# gcr_me18 register map
Registers are access not given, no defined reset value unless marked. A register's access mark holds for its fields unless they carry their own. Offsets are from the block's base; lines under a group give offsets from that group; [hi:lo] are bit positions; {n}, {i} and the like mark numbered series; 'fields as' and 'values as' point back to an identical list; <NAME> marks a mode.

## Memory map
0x40000000 GCR size 0x400 — Global Control Registers.

## GCR — Global Control Registers.
Base 0x40000000
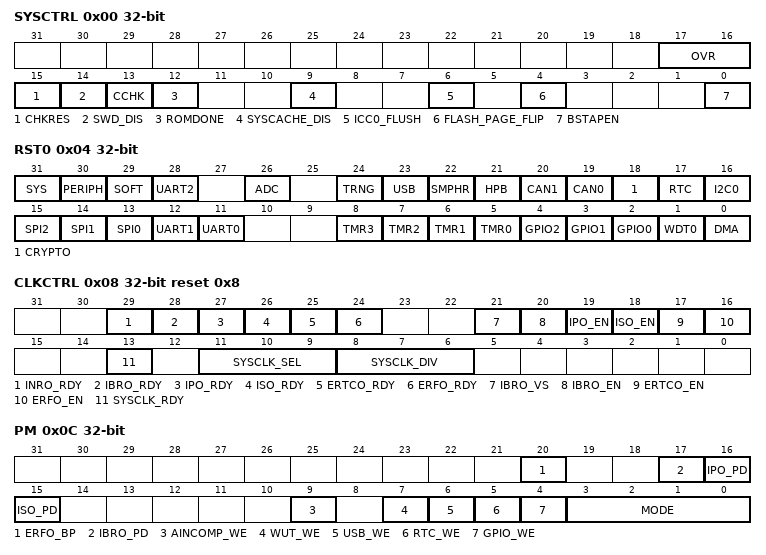
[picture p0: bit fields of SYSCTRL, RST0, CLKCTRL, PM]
0x00 SYSCTRL — System Control.
  [17:16] OVR — Operating Voltage Range.
    0=V0_9 (0.9V); 1=V1_0 (1.0V); 2=V1_1 (1.1V)
  [15] CHKRES — ROM Checksum Result. This bit is only valid when CHKRD=1.
    0=pass (ROM Checksum Correct.); 1=fail (ROM Checksum Fail.)
  [14] SWD_DIS — Serial Wire Debug Disable. This bit is used to disable the serial wire debug interface This bit is only writeable if (FMV lock word is not programmed) or if (ICE lock word is not programmed and the ROM_DONE bit is not set).
  [13] CCHK — Compute ROM Checksum. This bit is self-cleared when calculation is completed. Once set, software clearing this bit is ignored and the bit will remain set until the operation is completed.
    0=complete (No operation/complete.); 1=Start operation
  [12] ROMDONE — ROM_DONE status. Used to disable SWD interface during system initialization procedure
  [9] SYSCACHE_DIS — System Cache Disable.
  [6] ICC0_FLUSH — Code Cache Flush. This bit is used to flush the code caches and the instruction buffer of the Cortex-M4.
    0=Normal Code Cache Operation; 1=flush (Code Caches and CPU instruction buffer are flushed)
  [4] FLASH_PAGE_FLIP — Flips the Flash bottom and top halves. (Depending on the total flash size, each half is either 256K or 512K). Initiating a flash page flip will cause a flush of both the data buffer on the DCODE bus and the internal instruction buffer.
    0=normal (Physical layout matches logical layout.); 1=swapped (Bottom half mapped to logical top half and vice versa.)
  [0] BSTAPEN — Boundary Scan TAP enable. When enabled, the JTAG port is conneted to the Boundary Scan TAP instead of the ARM ICE.
0x04 RST0 — Reset.
  [all] fields
    0=reset_done (Reset complete.); 1=busy (Starts Reset or indicates reset in progress.)
  [31] SYS — System Reset. Setting this bit to 1 resets the CPU core and all peripherals, including the watchdog timer.
  [30] PERIPH — Peripheral Reset. Setting this bit to 1 resets all peripherals. The CPU core, the watchdog timer, and all GPIO pins are unaffected by this reset.
  [29] SOFT — Soft Reset. Setting this bit to 1 resets everything except the CPU and the watchdog timer.
  [28] UART2 — UART2 Reset. Setting this bit to 1 resets all UART 2 blocks.
  [26] ADC — ADC Reset.
  [24] TRNG — TRNG Reset. This reset is only available during the manufacture testing phase.
  [23] USB — USB Reset.
  [22] SMPHR — Semaphore Reset.
  [21] HPB — Hyperbus Reset.
  [20] CAN1 — CAN1 Reset.
  [19] CAN0 — CAN0 Reset.
  [18] CRYPTO — Crypto Reset.
  [17] RTC — Real Time Clock Reset.
  [16] I2C0 — I2C 0 Reset.
  [15] SPI2 — SPI 2 Reset. Setting this bit to 1 resets all SPI 2 blocks.
  [14] SPI1 — SPI 1 Reset. Setting this bit to 1 resets all SPI 1 blocks.
  [13] SPI0 — SPI 0 Reset. Setting this bit to 1 resets all SPI 0 blocks.
  [12] UART1 — UART 1 Reset. Setting this bit to 1 resets all UART 1 blocks.
  [11] UART0 — UART 0 Reset. Setting this bit to 1 resets all UART 0 blocks.
  [n+5] TMR{n} (n=0..3) — Timer {n} Reset. Setting this bit to 1 resets Timer {n} blocks.
  [4] GPIO2 — GPIO2 Reset. Setting this bit to 1 resets GPIO2 pins to their default states.
  [3] GPIO1 — GPIO1 Reset. Setting this bit to 1 resets GPIO1 pins to their default states.
  [2] GPIO0 — GPIO0 Reset. Setting this bit to 1 resets GPIO0 pins to their default states.
  [1] WDT0 — Watchdog Timer 0 Reset.
  [0] DMA — DMA Reset.
0x08 CLKCTRL reset 0x8 — Clock Control.
  [29] INRO_RDY ro — 8 kHz Low Frequency Reference Clock Ready.
    0=not (Is not Ready.); 1=ready (Is Ready.)
  [28] IBRO_RDY ro — 7.3725 MHz HIRC Ready.
    0=not (Is not Ready.); 1=ready (Is Ready.)
  [27] IPO_RDY ro — 100 MHz Clock Ready.
    0=not (Is not Ready.); 1=ready (Is Ready.)
  [26] ISO_RDY ro — 60 MHz Oscillator Ready.
    0=not (Is not Ready.); 1=ready (Is Ready.)
  [25] ERTCO_RDY ro — 32 kHz Crystal Oscillator Ready
    0=not (Is not Ready.); 1=ready (Is Ready.)
  [24] ERFO_RDY ro — 32 MHz Oscillator Ready
    0=not (Is not Ready.); 1=ready (Is Ready.)
  [21] IBRO_VS — 7.3725 MHz High Frequency Internal Reference Clock Voltage Select. This register bit is used to select the power supply to the IBRO.
    0=VCore Supply; 1=1V (Dedicated 1V regulated supply.)
  [20] IBRO_EN — 7.3725 MHz Clock Enable.
    0=dis (Is Disabled.); 1=en (Is Enabled.)
  [19] IPO_EN — 100 MHz Clock Enable.
    0=dis (Is Disabled.); 1=en (Is Enabled.)
  [18] ISO_EN — 60 MHz Internal Oscillator Enable.
    0=dis (Is Disabled.); 1=en (Is Enabled.)
  [17] ERTCO_EN — 32 kHz Oscillator Enable.
    0=dis (Is Disabled.); 1=en (Is Enabled.)
  [16] ERFO_EN — 32 MHz Crystal Oscillator Enable.
    0=dis (Is Disabled.); 1=en (Is Enabled.)
  [13] SYSCLK_RDY ro — Clock Ready. This read only bit reflects whether the currently selected system clock source is running.
    0=busy (Switchover to the new clock source (as selected by CLKSEL) has not yet occurred.); 1=ready (System clock running from CLKSEL clock source.)
  [11:9] SYSCLK_SEL — Clock Source Select. This 3 bit field selects the source for the system clock.
    0=ISO (The internal 60 MHz oscillator is used for the system clock.); 1=ITO (The internal 120 MHz PLL is used for the system clock.); 2=ERFO (The external 32 MHz input is used for the system clock.); 3=INRO (8 kHz LIRC is used for the system clock.); 4=IPO (The internal 100 MHz oscillator is used for the system clock.); 5=IBRO (The internal 7.3725 MHz oscillator is used for the system clock.); 6=ERTCO (External 32 kHz input is used for the system clock.); 7=EXTCLK (External clock input is used for the system clock.)
  [8:6] SYSCLK_DIV — Prescaler Select. This 3 bit field sets the system operating frequency by controlling the prescaler that divides the output of the PLL0.
    0=div1 (Divide by 1.); 1=div2 (Divide by 2.); 2=div4 (Divide by 4.); 3=div8 (Divide by 8.); 4=div16 (Divide by 16.); 5=div32 (Divide by 32.); 6=div64 (Divide by 64.); 7=div128 (Divide by 128.)
0x0C PM — Power Management.
  [20] ERFO_BP — ERFO Bypass.
  [17] IBRO_PD — 7.3725 MHz power down. This bit selects 7.3725 MHz clock power state in DEEPSLEEP mode.
    0=active (Mode is Active.); 1=deepsleep (Powered down in DEEPSLEEP.)
  [16] IPO_PD — 100 MHz power down. This bit selects 100 MHz clock power state in DEEPSLEEP mode.
    values as IBRO_PD
  [15] ISO_PD — 60 MHz power down. This bit selects the 60 MHz clock power state in DEEPSLEEP mode.
    values as IBRO_PD
  [9] AINCOMP_WE — AIN COMP Wake Up Enable. This bit enables AIN COMP as wakeup source.
    0=dis (Wake Up Disable.); 1=en (Wake Up Enable.)
  [7] WUT_WE — WUT Wake Up Enable. This bit enables the Wake-Up Timer as wakeup source.
    0=dis (Wake Up Disable.); 1=en (Wake Up Enable.)
  [6] USB_WE — USB Wake Up Enable. This bit enables USB IRQ as wakeup source
    0=dis (Wake Up Disable.); 1=en (Wake Up Enable.)
  [5] RTC_WE — RTC Alarm Wake Up Enable. This bit enables RTC alarm as wakeup source. If enabled, the desired RTC alarm must be configured via the RTC control registers.
    0=dis (Wake Up Disable.); 1=en (Wake Up Enable.)
  [4] GPIO_WE — GPIO Wake Up Enable. This bit enables all GPIO pins as potential wakeup sources. Any GPIO configured for wakeup is capable of causing an exit from IDLE or STANDBY modes when this bit is set.
    0=dis (Wake Up Disable.); 1=en (Wake Up Enable.)
  [3:0] MODE — Operating Mode. This two bit field selects the current operating mode for the device. Note that code execution only occurs during ACTIVE mode.
    0=Active Mode; 1=sleep (Cortex-M4 Active, RISC-V Sleep Mode.); 2=Standby Mode; 4=Backup Mode; 8=lpm (LPM or CM4 Deep Sleep Mode.); 9=upm; 10=Power Down Mode
0x10 PFRST rw — Power Fail Reset Register.
  [0] EN — Power Fail Reset Enable.
0x14 PFSTAT ro — Power Fail Reset Status Register.
  [1] RST — Power Fail Reset Status
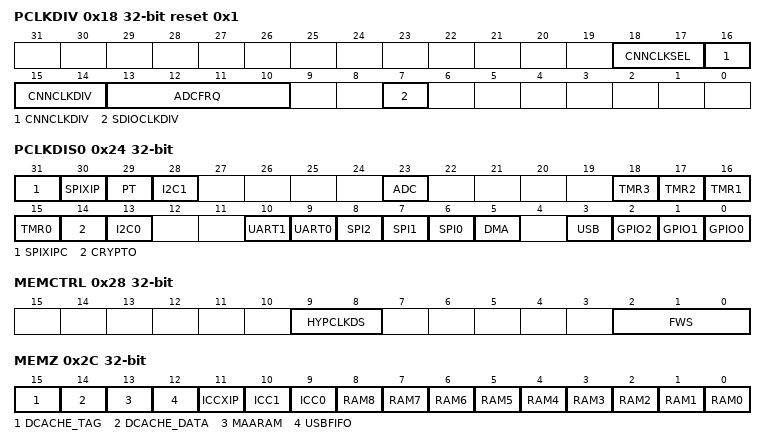
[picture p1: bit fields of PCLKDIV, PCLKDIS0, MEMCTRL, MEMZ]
0x18 PCLKDIV reset 0x1 — Peripheral Clock Divider.
  [18:17] CNNCLKSEL — CNN Clock Select.
    0=PCLK; 1=ISO; 3=ITO
  [16:14] CNNCLKDIV — CNN Clock Divider.
    0=div2; 1=div4; 2=div8; 3=div16; 4=div1
  [13:10] ADCFRQ — ADC clock Frequency. These bits define the ADC clock frequency. fADC = fPCLK / (ADCFRQ)
  [7] SDIOCLKDIV
    0=IPO_DIV2 (48 MHz); 1=IPO_DIV4 (24 MHz)
0x24 PCLKDIS0 — Peripheral Clock Disable.
  [all] fields
    0=en (enable it.); 1=dis (disable it.)
  [31] SPIXIPC — SPI XIPC Clock Disable.
  [30] SPIXIP — SPI XIP Clock Disable.
  [29] PT — Pluse Train Clock Disable.
  [28] I2C1 — I2C 1 Clock Disable.
  [23] ADC — ADC Clock Disable.
  [n+15] TMR{n} (n=0..3) — Timer {n} Clock Disable.
  [14] CRYPTO — Crypto Clock Disable.
  [13] I2C0 — I2C 0 Clock Disable.
  [10] UART1 — UART 1 Clock Disable.
  [9] UART0 — UART 0 Clock Disable.
  [8] SPI2 — SPI 2 Clock Disable.
  [7] SPI1 — SPI 1 Clock Disable.
  [6] SPI0 — SPI 0 Clock Disable.
  [5] DMA — DMA Clock Disable.
  [3] USB — USB Clock Disable.
  [2] GPIO2 — GPIO2 Clock Disable.
  [1] GPIO1 — GPIO1 Clock Disable.
  [0] GPIO0 — GPIO0 Clock Disable.
0x28 MEMCTRL — Memory Clock Control Register.
  [9:8] HYPCLKDS — HYP Clock Drive Strength Control.
  [2:0] FWS — Flash Wait State. These bits define the number of wait-state cycles per Flash data read access. Minimum wait state is 2.
0x2C MEMZ — Memory Zeroize Control.
  [all] fields
    0=nop (No operation/complete.); 1=Start operation
  [15] DCACHE_TAG — Data-Cache Controller Tag Zeroization.
  [14] DCACHE_DATA — Data-Cache Controller Data Zeroization.
  [13] MAARAM — MAA RAM Zeroization.
  [12] USBFIFO — USB FIFO Zeroization.
  [11] ICCXIP — ICC-XIP Zeroization.
  [10] ICC1 — Instruction Cache 1 Zeroization.
  [9] ICC0 — Instruction Cache 0 Zeroization.
  [n] RAM{n} (n=0..8) — System RAM Block {n} Zeroization.
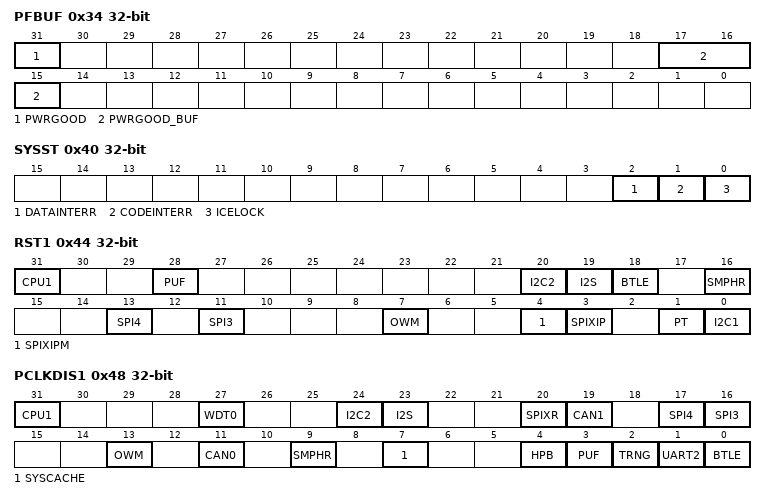
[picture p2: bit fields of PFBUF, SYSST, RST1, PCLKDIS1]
0x34 PFBUF ro — Power Fail Reset Buffer Register.
  [31] PWRGOOD — Power Good Detected.
  [17:15] PWRGOOD_BUF — Power Good Detection.
0x40 SYSST — System Status Register.
  [2] DATAINTERR — Data Interrupt Error Lock Status.
  [1] CODEINTERR — Code Interrupt Error Status.
  [0] ICELOCK — ARM ICE Lock Status.
    0=unlocked (ICE is unlocked.); 1=locked (ICE is locked.)
0x44 RST1 — Reset 1.
  [all] fields
    on read: 0=reset_done (Reset complete.); 1=busy (Starts reset or indicates reset in progress.)
  [31] CPU1 — CPU1 Reset.
  [28] PUF — PUF Reset.
  [20] I2C2 — I2C2 Reset.
  [19] I2S — I2S Reset.
  [18] BTLE — BTLE Reset.
  [16] SMPHR — SMPHR Reset.
  [13] SPI4 — SPI4 Reset.
  [11] SPI3 — SPI3 Reset.
  [7] OWM — OWM Reset.
  [4] SPIXIPM — SPI XIP Master Reset.
  [3] SPIXIP — SPI XIPF Reset.
  [1] PT — PT Reset.
  [0] I2C1 — I2C1 Reset.
0x48 PCLKDIS1 — Peripheral Clock Disable.
  [all] fields
    0=en (Clock enabled to the peripheral.); 1=dis (Clock disabled to the peripheral.)
  [31] CPU1 — CPU1 Clock Disable.
  [27] WDT0 — Watch Dog Timer 0 Clock Disable.
  [24] I2C2 — I2C2 Clock Disable.
  [23] I2S — I2S Clock Disable.
  [20] SPIXR — SPIXR Clock Disable.
  [19] CAN1 — CAN1 Clock Disable.
  [17] SPI4 — SPI4 Clock Disable.
  [16] SPI3 — SPI3 Clock Disable.
  [13] OWM — One-Wire Clock Disable.
  [11] CAN0 — CAN0 Clock Disable.
  [9] SMPHR — SMPHR Clock Disable.
  [7] SYSCACHE — System Cache Clock Disable.
  [4] HPB — HyperBus/Xccela Clock Disable.
  [3] PUF — PUF Clock Disable.
  [2] TRNG — TRNG Clock Disable.
  [1] UART2 — UART2 Clock Disable.
  [0] BTLE — BTLE Clock Disable.
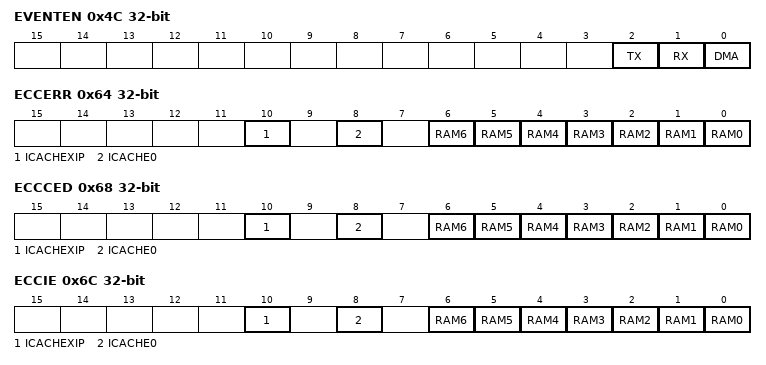
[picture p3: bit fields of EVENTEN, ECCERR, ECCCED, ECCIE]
0x4C EVENTEN — Event Enable Register.
  [2] TX — Enable TXEV pin event. When this bit is set, TXEV event from the CPU is output to GPIO1.9.
  [1] RX — Enable RXEV pin event. When this bit is set, RXEV event from the CPU is output to GPIO1.9.
  [0] DMA — Enable DMA event. When this bit is set, a DMA event will cause an RXEV event to wake the CPU from WFE sleep mode.
0x50 REVISION ro
  [15:0] REVISION — Manufacturer Chip Revision.
0x54 SYSIE — System Status Interrupt Enable Register.
  [0] ICEUNLOCK — ARM ICE Unlock Interrupt Enable.
    0=dis (disabled.); 1=en (enabled.)
0x64 ECCERR — ECC Error Register
  [10] ICACHEXIP — ECC System ICACHEXIP Error Flag. Write 1 to clear.
  [8] ICACHE0 — ECC System ICACHE0 Error Flag. Write 1 to clear.
  [n] RAM{n} (n=0..6) — ECC System RAM{n} Error Flag. Write 1 to clear.
0x68 ECCCED — ECC Not Double Error Detect Register
  fields as ECCERR
0x6C ECCIE — ECC IRQ Enable Register
  fields as ECCERR
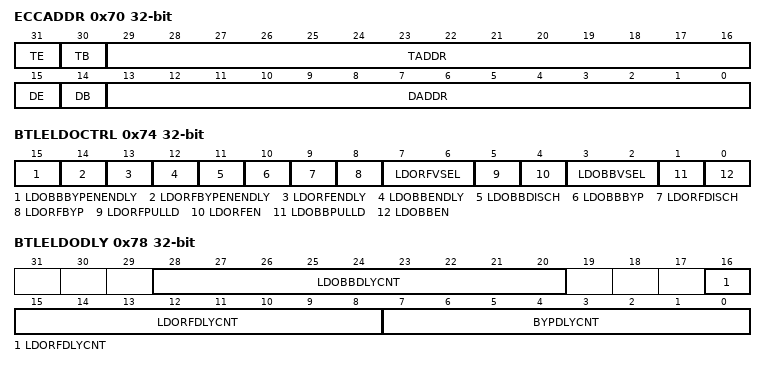
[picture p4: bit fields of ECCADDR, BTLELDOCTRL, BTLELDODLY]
0x70 ECCADDR — ECC Error Address Register
  [31] TE — Tag Error.
  [30] TB — Tag Error Bank.
  [29:16] TADDR — Tag Address.
  [15] DE — DE Error.
  [14] DB — Data Error Bank.
  [13:0] DADDR — Data Address.
0x74 BTLELDOCTRL — BTLE LDO Control Register
  [15] LDOBBBYPENENDLY — LDOBB Bypass Enable Delay.
  [14] LDORFBYPENENDLY — LDORF Bypass Enable Delay.
  [13] LDORFENDLY — LDORF Enable Delay.
  [12] LDOBBENDLY — LDOBB Enable Delay.
  [11] LDOBBDISCH — LDOBB Discharge.
  [10] LDOBBBYP — LDOBB Bypass Enable.
  [9] LDORFDISCH — LDORF Discharge.
  [8] LDORFBYP — LDORF Bypass Enable.
  [7:6] LDORFVSEL — LDORF Voltage Setting.
    0=0.85V; 1=0_9 (0.9V); 2=1.0V; 3=1.1V
  [5] LDORFPULLD — LDORF Pull Down.
  [4] LDORFEN — LDORF Enable.
  [3:2] LDOBBVSEL — LDOBB Voltage Setting.
    0=0.85V; 1=0_9 (0.9V); 2=1.0V; 3=1.1V
  [1] LDOBBPULLD — LDOBB Pull Down.
  [0] LDOBBEN — LDOBB Enable.
0x78 BTLELDODLY — BTLE LDO Delay Register
  [28:20] LDOBBDLYCNT — LDOBB Delay Count.
  [16:8] LDORFDLYCNT — LDORF Delay Count.
  [7:0] BYPDLYCNT — Bypass Delay Count.
0x80 GPR0 — General Purpose Register 0
